# ATSAMG55G19 device description
Architecture: CORTEX-M4; Family: SAMG; Series: SAMG55
Registers are 32-bit, read-write, no defined reset value unless marked. A register's access mark holds for its fields unless they carry their own. Offsets are from the block's base; [hi:lo] are bit positions; {n}, {i} and the like mark numbered series.

## CHIPID — Chip Identifier
Instances: CHIPID 0x400E0740
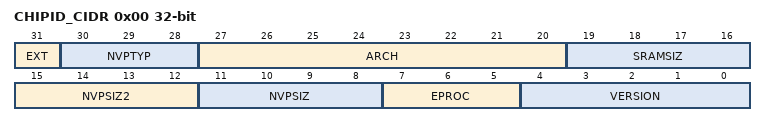
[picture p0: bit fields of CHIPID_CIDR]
0x00 CHIPID_CIDR ro — Chip ID Register
  [31] EXT — Extension Flag
  [30:28] NVPTYP — Nonvolatile Program Memory Type
    0=ROM; 1=ROMLESS (ROMless or on-chip Flash); 2=FLASH (Embedded Flash Memory); 3=ROM_FLASH (ROM and Embedded Flash Memory- NVPSIZ is ROM size- NVPSIZ2 is Flash size); 4=SRAM (SRAM emulating ROM)
  [27:20] ARCH — Architecture Identifier
    68=SAMG55 (SAM G55 (49-lead version))
  [19:16] SRAMSIZ — Internal SRAM Size
    0=_48K (48 Kbytes); 1=_192K (192 Kbytes); 2=_384K (384 Kbytes); 3=_6K (6 Kbytes); 4=_24K (24 Kbytes); 5=_4K (4 Kbytes); 6=_80K (80 Kbytes); 7=_160K (160 Kbytes); 8=_8K (8 Kbytes); 9=_16K (16 Kbytes); 10=_32K (32 Kbytes); 11=_64K (64 Kbytes); 12=_128K (128 Kbytes); 13=_256K (256 Kbytes); 14=_96K (96 Kbytes); 15=_512K (512 Kbytes)
  [15:12] NVPSIZ2 — Second Nonvolatile Program Memory Size
    0=NONE; 1=_8K (8 Kbytes); 2=_16K (16 Kbytes); 3=_32K (32 Kbytes); 5=_64K (64 Kbytes); 7=_128K (128 Kbytes); 9=_256K (256 Kbytes); 10=_512K (512 Kbytes); 12=_1024K (1024 Kbytes); 14=_2048K (2048 Kbytes)
  [11:8] NVPSIZ — Nonvolatile Program Memory Size
    0=NONE; 1=_8K (8 Kbytes); 2=_16K (16 Kbytes); 3=_32K (32 Kbytes); 5=_64K (64 Kbytes); 7=_128K (128 Kbytes); 8=_160K (160 Kbytes); 9=_256K (256 Kbytes); 10=_512K (512 Kbytes); 12=_1024K (1024 Kbytes); 14=_2048K (2048 Kbytes)
  [7:5] EPROC — Embedded Processor
    1=ARM946ES; 2=ARM7TDMI; 3=CM3 (Cortex-M3); 4=ARM920T; 5=ARM926EJS; 6=CA5 (Cortex-A5); 7=CM4 (Cortex-M4)
  [4:0] VERSION — Version of the Device
0x04 CHIPID_EXID ro — Chip ID Extension Register
  [31:0] EXID — Chip ID Extension

## CMCC — Cortex-M Cache Controller
Instances: CMCC 0x4003C000
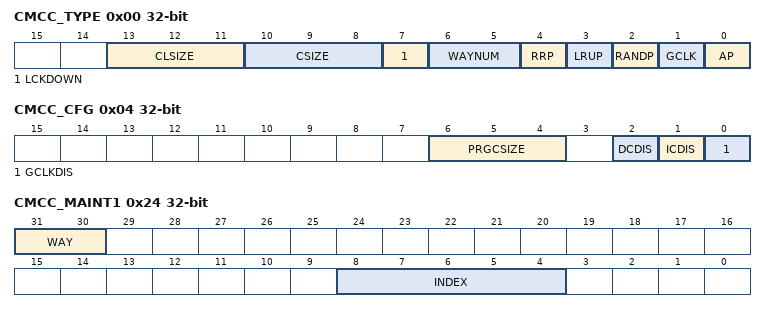
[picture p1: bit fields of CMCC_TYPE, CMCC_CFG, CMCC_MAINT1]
0x00 CMCC_TYPE ro — Cache Controller Type Register
  [13:11] CLSIZE — Cache LIne Size
    0=CLSIZE_1KB (Cache line size is 4 bytes); 1=CLSIZE_2KB (Cache line size is 8 bytes); 2=CLSIZE_4KB (Cache line size is 16 bytes); 3=CLSIZE_8KB (Cache line size is 32 bytes)
  [10:8] CSIZE — Data Cache Size
    0=CSIZE_1KB (Data cache size is 1 Kbyte); 1=CSIZE_2KB (Data cache size is 2 Kbytes); 2=CSIZE_4KB (Data cache size is 4 Kbytes); 3=CSIZE_8KB (Data cache size is 8 Kbytes)
  [7] LCKDOWN — Lockdown Supported
  [6:5] WAYNUM — Number of Ways
    0=DMAPPED (Direct Mapped Cache); 1=ARCH2WAY (2-way set associative); 2=ARCH4WAY (4-way set associative); 3=ARCH8WAY (8-way set associative)
  [4] RRP — Random Selection Policy Supported
  [3] LRUP — Least Recently Used Policy Supported
  [2] RANDP — Random Selection Policy Supported
  [1] GCLK — Dynamic Clock Gating Supported
  [0] AP — Access Port Access Allowed
0x04 CMCC_CFG — Cache Controller Configuration Register
  [6:4] PRGCSIZE
  [2] DCDIS
  [1] ICDIS
  [0] GCLKDIS — Disable Clock Gating
0x08 CMCC_CTRL wo — Cache Controller Control Register
  [0] CEN — Cache Controller Enable
0x0C CMCC_SR ro — Cache Controller Status Register
  [0] CSTS — Cache Controller Status
0x20 CMCC_MAINT0 wo — Cache Controller Maintenance Register 0
  [0] INVALL — Cache Controller Invalidate All
0x24 CMCC_MAINT1 wo — Cache Controller Maintenance Register 1
  [31:30] WAY — Invalidate Way
    {v}=Way {v} is selection for index invalidation (v=0..3)
  [8:4] INDEX — Invalidate Index
0x28 CMCC_MCFG — Cache Controller Monitor Configuration Register
  [1:0] MODE — Cache Controller Monitor Counter Mode
    0=CYCLE_COUNT (Cycle counter); 1=IHIT_COUNT (Instruction hit counter); 2=DHIT_COUNT (Data hit counter)
0x2C CMCC_MEN — Cache Controller Monitor Enable Register
  [0] MENABLE — Cache Controller Monitor Enable
0x30 CMCC_MCTRL wo — Cache Controller Monitor Control Register
  [0] SWRST — Monitor
0x34 CMCC_MSR ro — Cache Controller Monitor Status Register
  [31:0] EVENT_CNT — Monitor Event Counter

## Notices in the file
Copyright (c) 2017 Microchip Technology Inc.
SPDX-License-Identifier: Apache-2.0
Licensed under the Apache License, Version 2.0 (the "License");
you may not use this file except in compliance with the License.
You may obtain a copy of the License at
http://www.apache.org/licenses/LICENSE-2.0
Unless required by applicable law or agreed to in writing, software
distributed under the License is distributed on an "AS IS" BASIS,
WITHOUT WARRANTIES OR CONDITIONS OF ANY KIND, either express or implied.
See the License for the specific language governing permissions and
limitations under the License.
